# pse84 register map
Vendor: Cypress Semiconductor; Series: PSE84; File version: 1.0
CPU: CM33 r0p1, little endian, MPU, FPU, VTOR, 3 interrupt priority bits
Registers are 32-bit, read-write, reset 0x0 unless marked. A register's access mark holds for its fields unless they carry their own. Offsets are from the block's base; [hi:lo] are bit positions; lines under a group give offsets from that group; {n}, {i} and the like mark numbered series; 'fields as' and 'values as' point back to an identical list.

## ACTRLR (part 3 of 3) — Autonomnous Controller
Base 0x42ED0000
{0x800+0x20*i} TTCFG[{i}] (i=0..63) group — Timer Table Structure (only accessible if CTRL.EN=0)
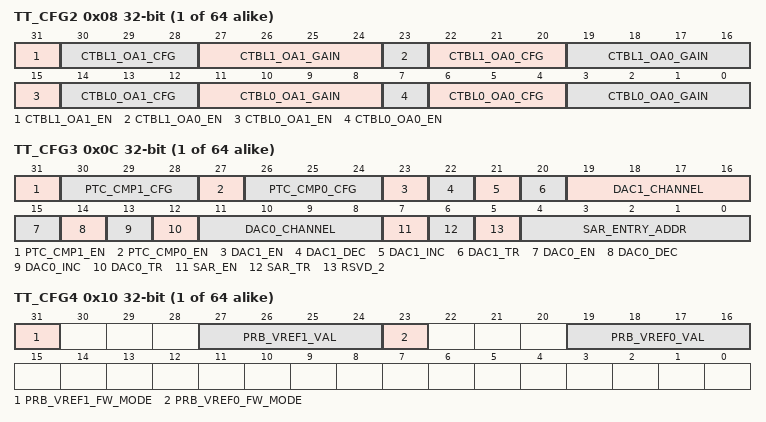
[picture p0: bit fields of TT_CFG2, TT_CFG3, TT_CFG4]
  0x08 TT_CFG2 — AC Table Configuration 2
    [31] CTBL1_OA1_EN — CTBL1 Opamp1 enable This field is only used by the Autonomous Controller if CTBL1_UNLOCK is set. Otherwise, the field is ignored.
      0=DISABLED (Disabled CTBL1 Opamp1 is powered down, comparator logic is reset and all CTBL1 OA1 AC conditions are cleared. CTBL1 configuration is retained.); 1=ENABLED (Enabled CTBL1 Opamp1 is powered and all logic is enabled and clocked.)
    [30:28] CTBL1_OA1_CFG — See CTBL0_OA0_CFG
    [27:24] CTBL1_OA1_GAIN — See CTBL0_OA0_GAIN
    [23] CTBL1_OA0_EN — See CTBL0_OA0_EN
    [22:20] CTBL1_OA0_CFG — See CTBL0_OA0_CFG
    [19:16] CTBL1_OA0_GAIN — See CTBL0_OA0_GAIN
    [15] CTBL0_OA1_EN — See CTBL0_OA0_EN
    [14:12] CTBL0_OA1_CFG — CTBL0 Opamp1 Mux Configuration This field determines the state of all input and reference muxes to the Opamp along with the output driver (i.e. if the oamp drives internal loads only or internal/external loads). This field is only used by the Autonomous Controller if CTBL0_UNLOCK is set. Otherwise, the field is ignored.
      {v}=CFG_{v} (Configuration {v} Mux settings determined by CTBL0_DYN_CFG_STRUCT_Regs{v}) (v=0..7)
    [11:8] CTBL0_OA1_GAIN — CTBL0 Opamp1 gain control. This field affects the value of the input (Rin) and feedback (Rfb) resistors. This field is only used by the Autonomous Controller if CTBL0_UNLOCK is set. Otherwise, the field is ignored. This field is only valid if CTBL0_STA_CFG_Regs.CFG.OA1_TOPO= 1 (PGA), 2 (TIA), 4 (Differential Amplifier) For PGA and Differential Amplifier configuration, both input and feedback resistors are used. For TIA configuration, only the feedback resistor is used. For Differential Amplifier configurations, CTBL0_OA0_GAIN must equal CTBL0_OA1_GAIN
      0=Rin = 192k, Rfb = 0 Gain of 1.00; 1=1_42 (Rin = 135k, Rfb = 57k Non-Inverting PGA: Gain of 1.42 Inverting PGA: Gain of 0.42 TIA: Rfb = 57k Differential Amplifier: Gain of 0.21); 2=2_00 (Rin = 96k, Rfb = 96k Non-Inverting PGA: Gain of 2.00 Inverting PGA: Gain of 1.00 TIA: Rfb = 96k Differential Amplifier: Gain of 0.50); 3=2_78 (Rin = 69k, Rfb = 123k Non-Inverting PGA: Gain of 2.78 Inverting PGA: Gain of 1.78 TIA: Rfb = 123k Differential Amplifier: Gain of 0.89); 4=4_00 (Rin = 48k, Rfb = 144k Non-Inverting PGA: Gain of 4.00 Inverting PGA: Gain of 3.00 TIA: Rfb = 144k Differential Amplifier: Gain of 1.50); 5=5_82 (Rin = 33k, Rfb = 159k Non-Inverting PGA: Gain of 5.82 Inverting PGA: Gain of 4.82 TIA: Rfb = 159k Differential Amplifier: Gain of 2.41); 6=8_00 (Rin = 24k, Rfb = 168k Non-Inverting PGA: Gain of 8.00 Inverting PGA: Gain of 7.00 TIA: Rfb = 168k Differential Amplifier: Gain of 3.50); 7=10_67 (Rin = 18k, Rfb = 174k Non-Inverting PGA: Gain of 10.67 Inverting PGA: Gain of 9.67 TIA: Rfb = 174k Differential Amplifier: Gain of 4.83); 8=16_00 (Rin = 12k, Rfb = 180k Non-Inverting PGA: Gain of 16.00 Inverting PGA: Gain of 15.00 TIA: Rfb = 180k Differential Amplifier: Gain of 7.50); 9=21_33 (Rin = 9k, Rfb = 183k Non-Inverting PGA: Gain of 21.33 Inverting PGA: Gain of 20.33 TIA: Rfb = 183k Differential Amplifier: Gain of 10.17); 10=32_00 (Rin = 6k, Rfb = 186k Non-Inverting PGA: Gain of 32.00 Inverting PGA: Gain of 31.00 TIA: Rfb = 186k Differential Amplifier: Gain of 15.50); {v}=RSVD_{v-11} (N/A) (v=11..15)
    [7] CTBL0_OA0_EN — CTBL0 Opamp0 enable This field is only used by the Autonomous Controller if CTBL0_UNLOCK is set. Otherwise, the field is ignored.
      0=DISABLED (Disabled CTBL0 Opamp0 is powered down, comparator logic is reset and all CTBL0 OA0 AC conditions are cleared. CTBL0 configuration is retained.); 1=ENABLED (Enabled CTBL0 Opamp0 is powered and all logic is enabled and clocked.)
    [6:4] CTBL0_OA0_CFG — CTBL0 Opamp0 Mux Configuration This field determines the state of all input and reference muxes to the Opamp along with the output driver (i.e. if the oamp drives internal loads only or internal/external loads). This field is only used by the Autonomous Controller if CTBL0_UNLOCK is set. Otherwise, the field is ignored.
      values as CTBL0_OA1_CFG
    [3:0] CTBL0_OA0_GAIN — CTBL0 Opamp0 gain control. This field affects the value of the input (Rin) and feedback (Rfb) resistors. This field is only used by the Autonomous Controller if CTBL0_UNLOCK is set. Otherwise, the field is ignored. This field is only valid if CTBL0_STA_CFG_Regs.CFG.OA0_TOPO= 1 (PGA), 2 (TIA), 4 (Differential Amplifier) For PGA and Differential Amplifier configuration, both input and feedback resistors are used. For TIA configuration, only the feedback resistor is used. For Differential Amplifier configurations, CTBL0_OA0_GAIN must equal CTBL0_OA1_GAIN
      0=Rin = 192k, Rfb = 0 Gain of 1.00; 1=1_42 (Rin = 135k, Rfb = 57k Non-Inverting PGA: Gain of 1.42 Inverting PGA: Gain of 0.42 TIA: Rfb = 57k Differential Amplifier: Gain of 0.42); 2=2_00 (Rin = 96k, Rfb = 96k Non-Inverting PGA: Gain of 2.00 Inverting PGA: Gain of 1.00 TIA: Rfb = 96k Differential Amplifier: Gain of 1.00); 3=2_78 (Rin = 69k, Rfb = 123k Non-Inverting PGA: Gain of 2.78 Inverting PGA: Gain of 1.78 TIA: Rfb = 123k Differential Amplifier: Gain of 1.78); 4=4_00 (Rin = 48k, Rfb = 144k Non-Inverting PGA: Gain of 4.00 Inverting PGA: Gain of 3.00 TIA: Rfb = 144k Differential Amplifier: Gain of 3.00); 5=5_82 (Rin = 33k, Rfb = 159k Non-Inverting PGA: Gain of 5.82 Inverting PGA: Gain of 4.82 TIA: Rfb = 159k Differential Amplifier: Gain of 4.82); 6=8_00 (Rin = 24k, Rfb = 168k Non-Inverting PGA: Gain of 8.00 Inverting PGA: Gain of 7.00 TIA: Rfb = 168k Differential Amplifier: Gain of 7.00); 7=10_67 (Rin = 18k, Rfb = 174k Non-Inverting PGA: Gain of 10.67 Inverting PGA: Gain of 9.67 TIA: Rfb = 174k Differential Amplifier: Gain of 9.67); 8=16_00 (Rin = 12k, Rfb = 180k Non-Inverting PGA: Gain of 16.00 Inverting PGA: Gain of 15.00 TIA: Rfb = 180k Differential Amplifier: Gain of 15.00); 9=21_33 (Rin = 9k, Rfb = 183k Non-Inverting PGA: Gain of 21.33 Inverting PGA: Gain of 20.33 TIA: Rfb = 183k Differential Amplifier: Gain of 20.33); 10=32_00 (Rin = 6k, Rfb = 186k Non-Inverting PGA: Gain of 32.00 Inverting PGA: Gain of 31.00 TIA: Rfb = 186k Differential Amplifier: Gain of 31.00); {v}=RSVD_{v-11} (N/A) (v=11..15)
  0x0C TT_CFG3 — AC Table Configuration 3
    [31] PTC_CMP1_EN — See PTC_CMP0_EN
    [30:28] PTC_CMP1_CFG — See PTC_CMP0_CFG
    [27] PTC_CMP0_EN — PTC Comparator0 enable This field is only used by the Autonomous Controller if PTC_UNLOCK is set. Otherwise, the field is ignored.
      0=DISABLED (Disabled PTC Comparator 0 is powered down, Comparator 0 logic is reset, and Comparator 0 clock is gated. PTC_COMP0 AC condition is cleared. PTC_STROBE0 and PTC_RANGE0 are functional if PTC_COMP1_EN is set. Otherwise those conditions are cleared/disabled. PTC Comparator 0 configuration is retained.); 1=ENABLED (Enabled PTC Comparator 0 is powered and all logic is enabled and clocked.)
    [26:24] PTC_CMP0_CFG — PTC Comp0 Mux Configuration This field determines the state of all input muxes to the Comparator 0. This field is only used by the Autonomous Controller if PTC_UNLOCK is set. Otherwise, the field is ignored.
      {v}=CFG_{v} (Configuration {v} Mux settings determined by PTC_DYN_CFG_STRUCT_Regs{v}) (v=0..7)
    [23] DAC1_EN — See DAC0_EN
    [22] DAC1_DEC — See DAC0_DEC
    [21] DAC1_INC — See DAC0_INC
    [20] DAC1_TR — See DAC0_TR
    [19:16] DAC1_CHANNEL — See DAC0_CHANNEL
    [15] DAC0_EN — DAC0 enable This field is only used by the Autonomous Controller if DAC0_UNLOCK is set. Otherwise, the field is ignored.
      0=DISABLED (Disabled DAC0 is powered down, DAC0 logic is reset, DAC0 clocks are gated, and all DAC0 AC conditions are cleared. DAC0 configuration and waveform tables are retained.); 1=ENABLED (Enabled DAC0 is powered and all logic is enabled and clocked.)
    [14] DAC0_DEC — DAC0 Decrement When entering a state where this field is set, the AC generates a single cycle pulse (decrement) to the DAC0 logic. DAC_INC and DAC_DEC CANNOT be simultaneously set in a given state (doing so will cause DAC_DEC to be ignored by the DAC0 logic). This field is only used by the DAC0 logic if the DAC0_CHANNEL field is set to 0-14 (Hardware channels) and DAC0.DAC_STA_CFG.CHAN_CFG.MODE = ADDR or DATA. If DAC0.DAC_STA_CFG.CHAN_CFG.MODE=ADDR, the DAC0 logic decrements the DAC address (Amount set by DAC0.DAC_STA_CFG.CHAN_CFG.STEP_SIZE_EN and STEP_SIZE_SEL) If DAC0.DAC_STA_CFG.CHAN_CFG.MODE=DATA, the DAC0 logic decrements the DAC Value (Amount set by CHAN_CFG.STEP_SIZE_EN and STEP_SIZE_SEL)
    [13] DAC0_INC — DAC0 Increment When entering a state where this field is set, the AC generates a single cycle pulse (increment) to the DAC0 logic. DAC_INC and DAC_DEC CANNOT be simultaneously set in a given state (doing so will cause DAC_DEC to be ignored by the DAC0 logic). This field is only used by the DAC0 logic if the DAC0_CHANNEL field is set to 0-14 (Hardware channels) and DAC0.DAC_STA_CFG.CHAN_CFG.MODE = ADDR or DATA. If DAC0.DAC_STA_CFG.CHAN_CFG.MODE=ADDR, the DAC0 logic increments the DAC address (Amount set by DAC0.DAC_STA_CFG.CHAN_CFG.STEP_SIZE_EN and STEP_SIZE_SEL) If DAC0.DAC_STA_CFG.CHAN_CFG.MODE=DATA, the DAC0 logic increments the DAC Value (Amount set by CHAN_CFG.STEP_SIZE_EN and STEP_SIZE_SEL)
    [12] DAC0_TR — DAC0 Trigger This field initiates DAC operation per the DAC0_CHANNEL selection. When entering a state where this field is set, the AC generates a single cycle pulse (trigger) to the DAC0 logic. This field is ignored unless: the DAC has been enabled in a prior state (DAC0_EN=1) and is ready (i.e. the AC has waited for BLOCK_READY in the same state where DAC0 was enabled). The DAC does NOT need to be disabled when switching channels.
    [11:8] DAC0_CHANNEL — DAC0 Channel select This field is pointer to the active DAC channel. Valid values are 0-15. This field is ignored unless the following conditions are guaranteed: 1. The DAC is triggered (DAC0_TR=1). 2. The DAC has been enabled in a prior state (DAC0_EN=1) and is ready (i.e. the AC has waited for BLOCK_READY in the same state where DAC0 was enabled).
      {v}=CHANNEL_{v} (Channel {v} Hardware Channel {v}: configured per DAC0.DAC_STA_CFG.CHAN_CFG{v} Writes to FW_DAC_VAL and FW_DAC_VAL_NXT are ignored.) (v=0..14); 15=FW_CHANNEL (FW Channel When selected, the DAC is configured for Firmware mode. If ACTRLR.STATUS.MODE=0, firmware can write to FW_DAC_VAL and FW_DAC_VAL_NXT. If ACTRLR.STATUS.MODE=1, firmware can only write to FW_DAC_VAL_NXT. Autonomus Controller DAC conditions, DAC0_INC, DAC0_DEC are not used in this mode.)
    [7] SAR_EN — SAR enable This field is only used by the Autonomous Controller if SAR_UNLOCK is set. Otherwise, the field is ignored.
      0=DISABLED (Disabled SAR is powered down, SAR logic (and FIRs) are reset, SAR/FIR clocks are gated, and all SAR AC conditions are cleared. SAR configuration and sequencer tables are retained. FIFO status and content is not cleared (i.e. the FIFO contents can still be read if the SAR is disabled).); 1=ENABLED (Enabled SAR is powered and all SAR (FIR) logic is enabled and clocked.)
    [6] SAR_TR — SAR Trigger (initiate SAR operation at sequencer address pointed to by SAR_ENTRY_ADDR) When entering a state where this field is set, the AC generates a single cycle pulse (trigger) to the SAR sequencer. This trigger is ignored by the SAR sequencer unless ALL of the following conditions are guaranteed: 1. The SAR has been enabled in a prior state (SAR_EN=1) and is ready (i.e. the AC has waited for BLOCK_READY in the same state where the SAR was enabled). 2. The SAR is idle (SAR.SAR_STA_CFG.STATUS.BUSY=0).
    [5] RSVD_2
    [4:0] SAR_ENTRY_ADDR — SAR Timer Table Entry State This field is a pointer to the entry address of the SAR sequencer state table. If ACTRLR.STATUS.MODE=0, this field points to the High Speed state table (SEQ.HS.DATA) If ACTRLR.STATUS.MODE=1, this field points to the Low Power state table (SEQ.LP.DATA) Valid values are 0-31. This field is ignored unless the following conditions are guaranteed: 1. The SAR is triggered (SAR_TR=1). 2. The SAR has been enabled in a prior state (SAR_EN=1) and is ready (i.e. the AC has waited for BLOCK_READY in the same state where the SAR was enabled). 3. The SAR is idle (SAR.SAR_STA_CFG.STATUS.BUSY=0). This field is pointer to the entry address of the SAR sequencer state table. If ACTRLR.STATUS.MODE=0, this field points to the High Speed state table (SEQ.HS.DATA) If ACTRLR.STATUS.MODE=1, this field points to the Low Power state table (SEQ.LP.DATA)
  0x10 TT_CFG4 — AC Table Configuration 4
    [31] PRB_VREF1_FW_MODE — See PRB_VREF0_FW_MODE
    [27:24] PRB_VREF1_VAL — See PRB_VREF0_VAL
    [23] PRB_VREF0_FW_MODE — PRB VREF0 Firmware Mode This field is only used by the Autonomous Controller if PRB_UNLOCK is set. Otherwise, the field is ignored. Prior to writing to this field, VREF0 must be enabled (PRB.VREF_CTRL0.EN=1).
      0=DISABLED (Disabled (PRB output determined by TT.CFG4.PRB_VREF0_VAL)); 1=ENABLED (Enabled (PRB output determined by PRB.PRB_VREF_CTRL0.VAL))
    [19:16] PRB_VREF0_VAL — TAP location for PRB VREF0. This field is only used by the Autonomous Controller if PRB_UNLOCK is set. Otherwise, the field is ignored. Prior the writing to this field, the following must be met: 1. PRB.VREF_CTRL0.EN=1 (VREF0 is enabled) 2. PRB_VREF0_FW_MODE = 0 (VREF0 is configured for Autonomous Controller control) The field is reset only when disabling the AC.
      0=TAP_0 (VREF0 = 0.06*PRB.VREF_CTRL.CFG); 1=TAP_1 (VREF0 = 0.13*PRB.VREF_CTRL.CFG); 2=TAP_2 (VREF0 = 0.19*PRB.VREF_CTRL.CFG); 3=TAP_3 (VREF0 = 0.25*PRB.VREF_CTRL.CFG); 4=TAP_4 (VREF0 = 0.31*PRB.VREF_CTRL.CFG); 5=TAP_5 (VREF0 = 0.38*PRB.VREF_CTRL.CFG); 6=TAP_6 (VREF0 = 0.44*PRB.VREF_CTRL.CFG); 7=TAP_7 (VREF0 = 0.50*PRB.VREF_CTRL.CFG); 8=TAP_8 (VREF0 = 0.56*PRB.VREF_CTRL.CFG); 9=TAP_9 (VREF0 = 0.63*PRB.VREF_CTRL.CFG); 10=TAP_10 (VREF0 = 0.69*PRB.VREF_CTRL.CFG); 11=TAP_11 (VREF0 = 0.75*PRB.VREF_CTRL.CFG); 12=TAP_12 (VREF0 = 0.81*PRB.VREF_CTRL.CFG); 13=TAP_13 (VREF0 = 0.88*PRB.VREF_CTRL.CFG); 14=TAP_14 (VREF0 = 0.94*PRB.VREF_CTRL.CFG); 15=TAP_15 (VREF0 = 1.00*PRB.VREF_CTRL.CFG)
